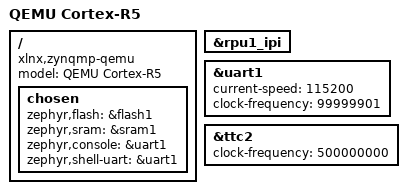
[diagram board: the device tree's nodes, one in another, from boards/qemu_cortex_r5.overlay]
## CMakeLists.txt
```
# SPDX-License-Identifier: Apache-2.0

cmake_minimum_required(VERSION 3.20.0)

find_package(Zephyr REQUIRED HINTS $ENV{ZEPHYR_BASE})
project(ipm_xlnx)

target_include_directories(app PRIVATE ${ZEPHYR_BASE}/drivers)
target_sources(app PRIVATE src/main.c)
```

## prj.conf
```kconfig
CONFIG_STDOUT_CONSOLE=n
CONFIG_PRINTK=y
CONFIG_IPM=y
CONFIG_XLNX_IPI=y
CONFIG_XLNX_PSTTC_TIMER_INDEX=2
CONFIG_SERIAL_INIT_PRIORITY=35
```

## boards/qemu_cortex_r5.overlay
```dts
/*
 * Copyright (c) 2019 Lexmark International, Inc.
 * Copyright (c) 2023 AMD-Xilinx, Inc.
 *
 * SPDX-License-Identifier: Apache-2.0
 *
 */

#include <arm/xilinx/zynqmp_rpu1.dtsi>

/ {
	model = "QEMU Cortex-R5";
	compatible = "xlnx,zynqmp-qemu";

	chosen {
		zephyr,flash = &flash1;
		zephyr,sram = &sram1;
		zephyr,console = &uart1;
		zephyr,shell-uart = &uart1;
	};
};

&rpu1_ipi {
	status = "okay";
};

&uart1 {
	status = "okay";
	current-speed = <115200>;
	clock-frequency = <99999901>;
};

&ttc2 {
	status = "okay";
	clock-frequency = <500000000>;
};
```

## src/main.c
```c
/*
 * Copyright (c) 2023, AMD-Xilinx
 *
 * SPDX-License-Identifier: Apache-2.0
 */

#include <string.h>
#include <zephyr/kernel.h>
#include <zephyr/sys/printk.h>
#include <zephyr/device.h>
#include <zephyr/drivers/ipm.h>

#define RPU_CORE_ID 1
#define apu_mbox_label rpu1_apu_mailbox
#define rpu_mbox_label rpu1_rpu0_mailbox
#define TEST_STR       "ping from RPU1"

struct xlnx_ipi_data {
	size_t len;
	void *user_data;
	uint8_t data[];
};

static void apu_ipm_callback(const struct device *dev, void *context, uint32_t id,
			     volatile void *data)
{
	struct xlnx_ipi_data *msg = (struct xlnx_ipi_data *)data;
	int status;

	printk("RPU%d rx: %s\n", RPU_CORE_ID, msg->data);

	/* echo back to Remote processor */
	status = ipm_send(dev, 0, id, msg->data, msg->len);
	if (status) {
		printk("ipm_send() failed: %d\n", status);
	}
}

static void rpu_ipm_callback(const struct device *dev, void *context, uint32_t id,
			     volatile void *data)
{
	struct xlnx_ipi_data *msg = (struct xlnx_ipi_data *)data;

	printk("RPU%d rx: %s\n", RPU_CORE_ID, msg->data);
}

void main(void)
{
	const struct device *apu_ipm, *rpu_ipm;
	int status;

	/* ping APU */
	apu_ipm = DEVICE_DT_GET(DT_NODELABEL(apu_mbox_label));
	if (!device_is_ready(apu_ipm)) {
		printk("error: device isn't ready\n");
		while (1) {
			;
		}
	}

	ipm_register_callback(apu_ipm, apu_ipm_callback, NULL);

	if (ipm_set_enabled(apu_ipm, 1) != 0) {
		printk("interrupt is not enabled\n");
	}

	rpu_ipm = DEVICE_DT_GET(DT_NODELABEL(rpu_mbox_label));
	if (!device_is_ready(rpu_ipm)) {
		printk("error: device isn't ready\n");
		while (1) {
			;
		}
	}

	ipm_register_callback(rpu_ipm, rpu_ipm_callback, NULL);

	if (ipm_set_enabled(rpu_ipm, 1) != 0) {
		printk("interrupt is not enabled\n");
	}

	while (1) {
		status = ipm_send(rpu_ipm, 0, 0, TEST_STR, strlen(TEST_STR));
		if (status) {
			printk("ipm_send() failed: %d\n", status);
		}
		k_sleep(K_MSEC(1000));
	}
}
```
